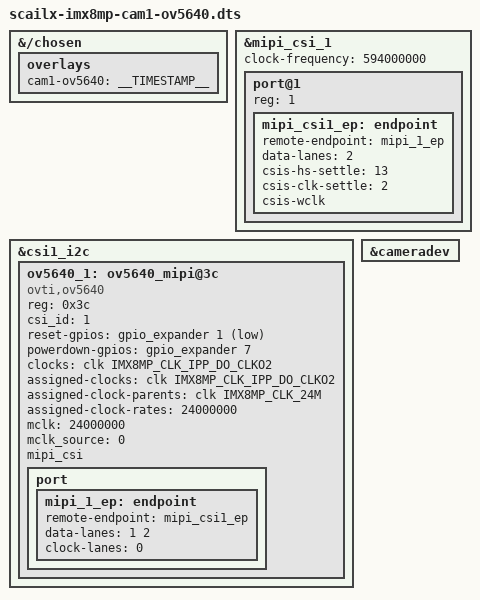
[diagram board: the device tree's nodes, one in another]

// CSI Camera Module 5MP OV5640 on CSI-0

/dts-v1/;
/plugin/;

#include <dt-bindings/clock/imx8mp-clock.h>
#include <dt-bindings/gpio/gpio.h>

&{/chosen} {
	overlays {
		cam1-ov5640 = __TIMESTAMP__;
	};
};

&mipi_csi_1 {
	#address-cells = <1>;
	#size-cells = <0>;
	clock-frequency = <594000000>;
	status = "okay";

	port@1 {
		reg = <1>;
		mipi_csi1_ep: endpoint {
			remote-endpoint = <&mipi_1_ep>;
			data-lanes = <2>;
			csis-hs-settle = <13>;
			csis-clk-settle = <2>;
			csis-wclk;
		};
	};
};

&csi1_i2c {
	#address-cells = <1>;
	#size-cells = <0>;

	ov5640_1: ov5640_mipi@3c {
		compatible = "ovti,ov5640";
		reg = <0x3c>;
		csi_id = <1>;
		reset-gpios = <&gpio_expander 1 GPIO_ACTIVE_LOW>;
		powerdown-gpios = <&gpio_expander 7 GPIO_ACTIVE_HIGH>;
		clocks = <&clk IMX8MP_CLK_IPP_DO_CLKO2>;
		clock-names = "xclk";
		assigned-clocks = <&clk IMX8MP_CLK_IPP_DO_CLKO2>;
		assigned-clock-parents = <&clk IMX8MP_CLK_24M>;
		assigned-clock-rates = <24000000>;
		mclk = <24000000>;
		mclk_source = <0>;
		mipi_csi;
		status = "okay";

		port {
			mipi_1_ep: endpoint {
				remote-endpoint = <&mipi_csi1_ep>;
				data-lanes = <1 2>;
				clock-lanes = <0>;
			};
		};
	};
};

&cameradev {
	status = "okay";
};

